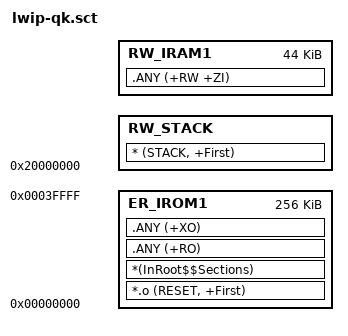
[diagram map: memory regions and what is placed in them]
; *************************************************************
; *** Scatter-Loading Description File generated by uVision ***
; LM3S6965 IROM 256 KiB, IRAM 46 KiB
;
; Modified by Quantum Leaps:
; added STACK as the *first* section in RW_STACK
; *************************************************************

LR_IROM1 0x00000000 0x00040000  {    ; load region size_region
  ER_IROM1 0x00000000 0x00040000  {  ; load address = execution address
   *.o (RESET, +First)
   *(InRoot$$Sections)
   .ANY (+RO)
   .ANY (+XO)
  }

  ; RAM base=0x20000000 len=0x0000B800
  RW_STACK 0x20000000 {              ; <== Quantum Leaps 
   * (STACK, +First)
  }
  RW_IRAM1 +0 (0x0000B800 - 2048) {  ; NOTE: 2048 assumeed STACK size!
   .ANY (+RW +ZI)
  }
}

